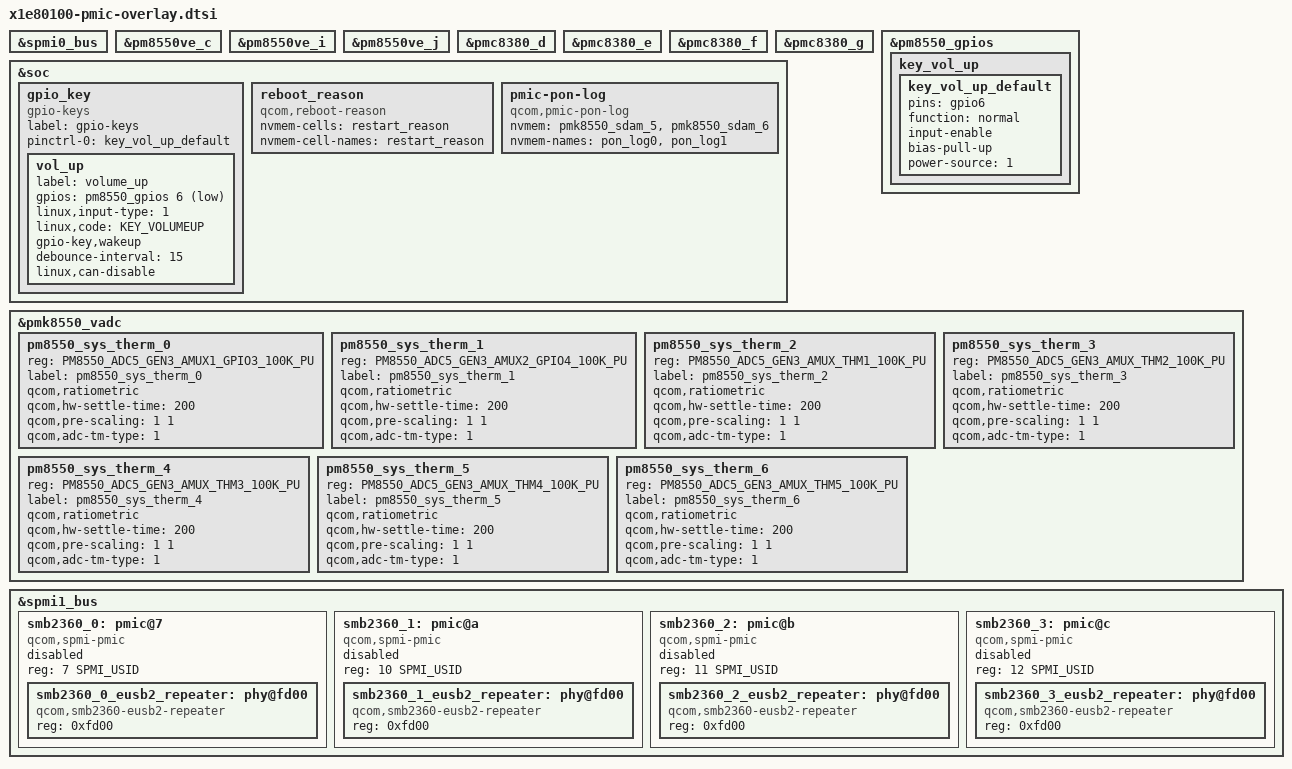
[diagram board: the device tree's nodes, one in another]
// SPDX-License-Identifier: BSD-3-Clause
/*
 * Copyright (c) Qualcomm Technologies, Inc. and/or its subsidiaries.
 */

#include <dt-bindings/gpio/gpio.h>
#include <dt-bindings/input/input.h>
#include <dt-bindings/input/linux-event-codes.h>
#include <dt-bindings/interrupt-controller/irq.h>
#include <dt-bindings/spmi/spmi.h>

&spmi0_bus {
	#include "pmk8550.dtsi"
	#include "pm8550.dtsi"
	#include "pm8550ve.dtsi"
	#include "pmc8380.dtsi"
	#include "pm8010.dtsi"
};

&pm8550ve_c {
	status = "ok";
};

&pm8550ve_i {
	status = "ok";
};

&pm8550ve_j {
	status = "ok";
};

&pmc8380_d {
	status = "ok";
};

&pmc8380_e {
	status = "ok";
};

&pmc8380_f {
	status = "ok";
};

&pmc8380_g {
	status = "ok";
};

&pm8550_gpios {
	key_vol_up {
		key_vol_up_default: key_vol_up_default {
			pins = "gpio6";
			function = "normal";
			input-enable;
			bias-pull-up;
			power-source = <1>;
		};
	};
};

&soc {
	gpio_key {
		compatible = "gpio-keys";
		label = "gpio-keys";
		pinctrl-names = "default";
		pinctrl-0 = <&key_vol_up_default>;
		vol_up {
			label = "volume_up";
			gpios = <&pm8550_gpios 6 GPIO_ACTIVE_LOW>;
			linux,input-type = <1>;
			linux,code = <KEY_VOLUMEUP>;
			gpio-key,wakeup;
			debounce-interval = <15>;
			linux,can-disable;
		};
	};

	reboot_reason {
		compatible = "qcom,reboot-reason";
		nvmem-cells = <&restart_reason>;
		nvmem-cell-names = "restart_reason";
	};

	pmic-pon-log {
		compatible = "qcom,pmic-pon-log";
		nvmem = <&pmk8550_sdam_5>, <&pmk8550_sdam_6>;
		nvmem-names = "pon_log0", "pon_log1";
	};
};

&pmk8550_vadc {
	pm8550_sys_therm_0 {
		reg = <PM8550_ADC5_GEN3_AMUX1_GPIO3_100K_PU>;
		label = "pm8550_sys_therm_0";
		qcom,ratiometric;
		qcom,hw-settle-time = <200>;
		qcom,pre-scaling = <1 1>;
		qcom,adc-tm-type = <1>;
	};

	pm8550_sys_therm_1 {
		reg = <PM8550_ADC5_GEN3_AMUX2_GPIO4_100K_PU>;
		label = "pm8550_sys_therm_1";
		qcom,ratiometric;
		qcom,hw-settle-time = <200>;
		qcom,pre-scaling = <1 1>;
		qcom,adc-tm-type = <1>;
	};

	pm8550_sys_therm_2 {
		reg = <PM8550_ADC5_GEN3_AMUX_THM1_100K_PU>;
		label = "pm8550_sys_therm_2";
		qcom,ratiometric;
		qcom,hw-settle-time = <200>;
		qcom,pre-scaling = <1 1>;
		qcom,adc-tm-type = <1>;
	};

	pm8550_sys_therm_3 {
		reg = <PM8550_ADC5_GEN3_AMUX_THM2_100K_PU>;
		label = "pm8550_sys_therm_3";
		qcom,ratiometric;
		qcom,hw-settle-time = <200>;
		qcom,pre-scaling = <1 1>;
		qcom,adc-tm-type = <1>;
	};

	pm8550_sys_therm_4 {
		reg = <PM8550_ADC5_GEN3_AMUX_THM3_100K_PU>;
		label = "pm8550_sys_therm_4";
		qcom,ratiometric;
		qcom,hw-settle-time = <200>;
		qcom,pre-scaling = <1 1>;
		qcom,adc-tm-type = <1>;
	};

	pm8550_sys_therm_5 {
		reg = <PM8550_ADC5_GEN3_AMUX_THM4_100K_PU>;
		label = "pm8550_sys_therm_5";
		qcom,ratiometric;
		qcom,hw-settle-time = <200>;
		qcom,pre-scaling = <1 1>;
		qcom,adc-tm-type = <1>;
	};

	pm8550_sys_therm_6 {
		reg = <PM8550_ADC5_GEN3_AMUX_THM5_100K_PU>;
		label = "pm8550_sys_therm_6";
		qcom,ratiometric;
		qcom,hw-settle-time = <200>;
		qcom,pre-scaling = <1 1>;
		qcom,adc-tm-type = <1>;
	};
};

&spmi1_bus {
	smb2360_0: pmic@7 {
		compatible = "qcom,spmi-pmic";
		reg = <7 SPMI_USID>;
		#address-cells = <1>;
		#size-cells = <0>;

		status = "disabled";

		smb2360_0_eusb2_repeater: phy@fd00 {
			compatible = "qcom,smb2360-eusb2-repeater";
			reg = <0xfd00>;
			#phy-cells = <0>;
		};
	};

	smb2360_1: pmic@a {
		compatible = "qcom,spmi-pmic";
		reg = <10 SPMI_USID>;
		#address-cells = <1>;
		#size-cells = <0>;

		status = "disabled";

		smb2360_1_eusb2_repeater: phy@fd00 {
			compatible = "qcom,smb2360-eusb2-repeater";
			reg = <0xfd00>;
			#phy-cells = <0>;
		};
	};

	smb2360_2: pmic@b {
		compatible = "qcom,spmi-pmic";
		reg = <11 SPMI_USID>;
		#address-cells = <1>;
		#size-cells = <0>;

		status = "disabled";

		smb2360_2_eusb2_repeater: phy@fd00 {
			compatible = "qcom,smb2360-eusb2-repeater";
			reg = <0xfd00>;
			#phy-cells = <0>;
		};
	};

	smb2360_3: pmic@c {
		compatible = "qcom,spmi-pmic";
		reg = <12 SPMI_USID>;
		#address-cells = <1>;
		#size-cells = <0>;

		status = "disabled";

		smb2360_3_eusb2_repeater: phy@fd00 {
			compatible = "qcom,smb2360-eusb2-repeater";
			reg = <0xfd00>;
			#phy-cells = <0>;
		};
	};
};
